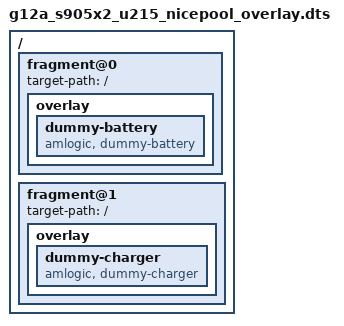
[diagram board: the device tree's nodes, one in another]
/*
 * arch/arm64/boot/dts/amlogic/g12a_s905x2_u215_nicepool_overlay.dts
 *
 * Copyright (C) 2017 Amlogic, Inc. All rights reserved.
 *
 * This program is free software; you can redistribute it and/or modify
 * it under the terms of the GNU General Public License as published by
 * the Free Software Foundation; either version 2 of the License, or
 * (at your option) any later version.
 *
 * This program is distributed in the hope that it will be useful, but WITHOUT
 * ANY WARRANTY; without even the implied warranty of MERCHANTABILITY or
 * FITNESS FOR A PARTICULAR PURPOSE.  See the GNU General Public License for
 * more details.
 *
 */

/dts-v1/;
/plugin/;

/ {
	fragment@0 {
	target-path = "/";

	overlay {

		dummy-battery {
			compatible = "amlogic, dummy-battery";
			status = "okay";
			};
		};
	};

	fragment@1 {
	target-path = "/";

	overlay {

		dummy-charger {
			compatible = "amlogic, dummy-charger";
			status = "okay";
			};
		};
	};
};
